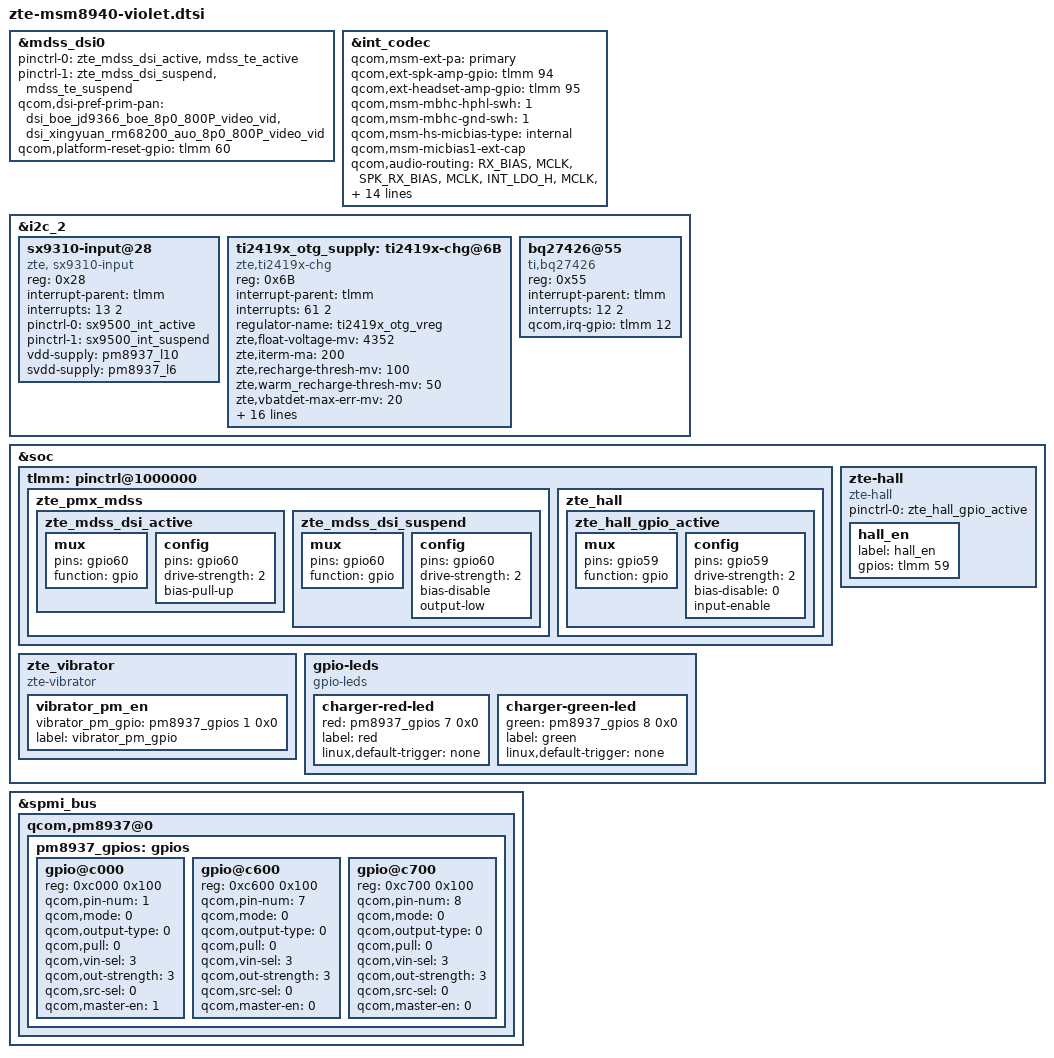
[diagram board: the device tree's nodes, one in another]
/*
 * device tree for zte bolton board
 */
#include "dsi-panel-zte-boe-jd9366-boe-8p0-800p-video.dtsi"
#include "dsi-panel-zte-xingyuan-rm68200-auo-8p0-800p-video.dtsi"
#include "touch-key-backlight-violet.dtsi"

&mdss_dsi0 {
	pinctrl-names = "mdss_default", "mdss_sleep";
	pinctrl-0 = <&zte_mdss_dsi_active &mdss_te_active>;
	pinctrl-1 = <&zte_mdss_dsi_suspend &mdss_te_suspend>;
	qcom,dsi-pref-prim-pan = <&dsi_boe_jd9366_boe_8p0_800P_video_vid &dsi_xingyuan_rm68200_auo_8p0_800P_video_vid>;
	qcom,platform-reset-gpio = <&tlmm 60 0>;
};

&int_codec {
	qcom,msm-ext-pa = "primary";
	qcom,ext-spk-amp-gpio = <&tlmm 94 0>;
	qcom,ext-headset-amp-gpio = <&tlmm 95 0>;
	qcom,msm-mbhc-hphl-swh = <1>;
	qcom,msm-mbhc-gnd-swh = <1>;
	qcom,msm-hs-micbias-type = "internal";
	qcom,msm-micbias1-ext-cap;
	qcom,audio-routing =
		"RX_BIAS", "MCLK",
		"SPK_RX_BIAS", "MCLK",
		"INT_LDO_H", "MCLK",
		"MIC BIAS External", "Handset Mic",
		"MIC BIAS Internal2", "Headset Mic",
		"MIC BIAS External", "Secondary Mic",
		"AMIC1", "MIC BIAS External",
		"AMIC2", "MIC BIAS Internal2",
		"AMIC3", "MIC BIAS External",
		"Lineout_hph amp", "HEADPHONE",
		"WSA_SPK OUT", "VDD_WSA_SWITCH",
		"SpkrMono WSA_IN", "WSA_SPK OUT";
	qcom,msm-gpios =
			"pri_i2s";
	qcom,pinctrl-names =
			"all_off",
			"pri_i2s_act";
	pinctrl-names =
			"all_off",
			"pri_i2s_act";
	pinctrl-0 = <&cdc_pdm_lines_sus &cdc_pdm_lines_2_sus >;
	pinctrl-1 = <&cdc_pdm_lines_act &cdc_pdm_lines_2_act >;

};

&i2c_2 {
	sx9310-input@28 {
		compatible = "zte, sx9310-input";
		reg = <0x28>;
		//cc,irq_gpio = <&tlmm 13 0x0>;
		interrupt-parent = <&tlmm>;
		interrupts = <13 2>;
		interrupt-names = "sx9310_irq";
		pinctrl-names = "sx9310_active", "sx9310_sleep";
		pinctrl-0 = <&sx9500_int_active>;
		pinctrl-1 = <&sx9500_int_suspend >;
		vdd-supply = <&pm8937_l10>;
		svdd-supply = <&pm8937_l6>;
	};

	ti2419x_otg_supply: ti2419x-chg@6B {
		compatible = "zte,ti2419x-chg";
		reg = <0x6B>;
		interrupt-parent = <&tlmm>;
		interrupts = <61 2>;
		pinctrl-names = "default";
		/*pinctrl-0 = <&smb_int_default>;*/
		regulator-name = "ti2419x_otg_vreg";

		zte,float-voltage-mv = <4352>;
		zte,iterm-ma = <200>;
		/*zte,hw-iterm-disabled;*/
		/*zte,charging-disabled; changed by zte */
		zte,recharge-thresh-mv = <100>;
		zte,warm_recharge-thresh-mv = <50>;
		zte,vbatdet-max-err-mv = <20>;
		zte,charging-timeout = <10>;
		zte,input_voltage_mv = <4520>;
		zte,max_usb_current = <2100>;
		zte,max_battery_current = <3000>;
		zte,thermal-mitigation = <2100 1500 900 500 0>;
		zte,warm_bat_mv = <4100>;
		zte,cool_bat_mv = <4208>;
		zte,warm-bat-decidegc = <440>;
		zte,cool-bat-decidegc = <100>;
		zte,hot-bat-decidegc = <500>;
		zte,cold-bat-decidegc = <20>;
		zte,warm_bat_chg_ma = <512>;
		zte,cool_bat_chg_ma = <512>;
		qcom,tichg-vadc = <&pm8937_vadc>;
		zte,batt-hot-percentage = <20>; /*Only for k81:-5~49*/
		zte,batt-cold-percentage= <75>; /*Only for k81:-5~49*/
	};

	bq27426@55 {
		compatible = "ti,bq27426";
		reg = <0x55>;
		interrupt-parent = <&tlmm>;
		interrupts = <12 2>;
		qcom,irq-gpio = <&tlmm 12 0x0>;
	};
};

&soc {
	tlmm: pinctrl@1000000 {
		zte_pmx_mdss: zte_pmx_mdss {
			zte_mdss_dsi_active: zte_mdss_dsi_active {
				mux {
					pins = "gpio60";
					function = "gpio";
				};

				config {
					pins = "gpio60";
					drive-strength = <2>; /* 2 mA */
					bias-pull-up;
				};
			};
			zte_mdss_dsi_suspend: zte_mdss_dsi_suspend {
				mux {
					pins = "gpio60";
					function = "gpio";
				};

				config {
					pins = "gpio60";
					drive-strength = <2>; /* 2 mA */
					bias-disable; /* no pullup */
					output-low;
				};
			};
		};
		zte_hall: zte_hall {
			zte_hall_gpio_active: zte_hall_gpio_active {
				mux {
					pins = "gpio59";
					function = "gpio";
				};
				config {
					pins = "gpio59";
					drive-strength = <2>; /* 2 mA */
					bias-disable = <0>; /* no pull */
					input-enable; /* input */
				};
			};
		};
	};
};

&soc {
	zte-hall {
		compatible = "zte-hall";
		pinctrl-names = "zte_hall_gpio_active";
		pinctrl-0 = <&zte_hall_gpio_active>;
		hall_en{
			label = "hall_en";
			gpios = <&tlmm 59 0x0>;
		};
	};

	zte_vibrator {
		compatible = "zte-vibrator";
		vibrator_pm_en{
			vibrator_pm_gpio = <&pm8937_gpios 1 0x0>;
			label = "vibrator_pm_gpio";
		};
	};

	gpio-leds {
		compatible = "gpio-leds";
		charger-red-led {
			red = <&pm8937_gpios 7 0x0>;
			label = "red";
			linux,default-trigger = "none";
		};
	};

	gpio-leds {
		compatible = "gpio-leds";
		charger-green-led {
			green = <&pm8937_gpios 8 0x0>;
			label = "green";
			linux,default-trigger = "none";
		};
	};
};

&spmi_bus {
	qcom,pm8937@0 {
		pm8937_gpios: gpios {
			gpio@c000 {
				reg = <0xc000 0x100>;
				qcom,pin-num = <1>;
				qcom,mode = <0>;
				qcom,output-type = <0>;
				qcom,pull = <0>;
				qcom,vin-sel = <3>;
				qcom,out-strength = <3>;
				qcom,src-sel = <0>;
				qcom,master-en = <1>;
				//qcom,dtest-sel = <1>;
				status = "okay";
			};

			gpio@c600 {
				reg = <0xc600 0x100>;
				qcom,pin-num = <7>;
				qcom,mode = <0>;
				qcom,output-type = <0>;
				qcom,pull = <0>;
				qcom,vin-sel = <3>;
				qcom,out-strength = <3>;
				qcom,src-sel = <0>;
				qcom,master-en = <0>;
				//qcom,dtest-sel = <1>;
				status = "okay";
			};

			gpio@c700 {
				reg = <0xc700 0x100>;
				qcom,pin-num = <8>;
				qcom,mode = <0>;
				qcom,output-type = <0>;
				qcom,pull = <0>;
				qcom,vin-sel = <3>;
				qcom,out-strength = <3>;
				qcom,src-sel = <0>;
				qcom,master-en = <0>;
				//qcom,dtest-sel = <1>;
				status = "okay";
			};
		};
	};
};
